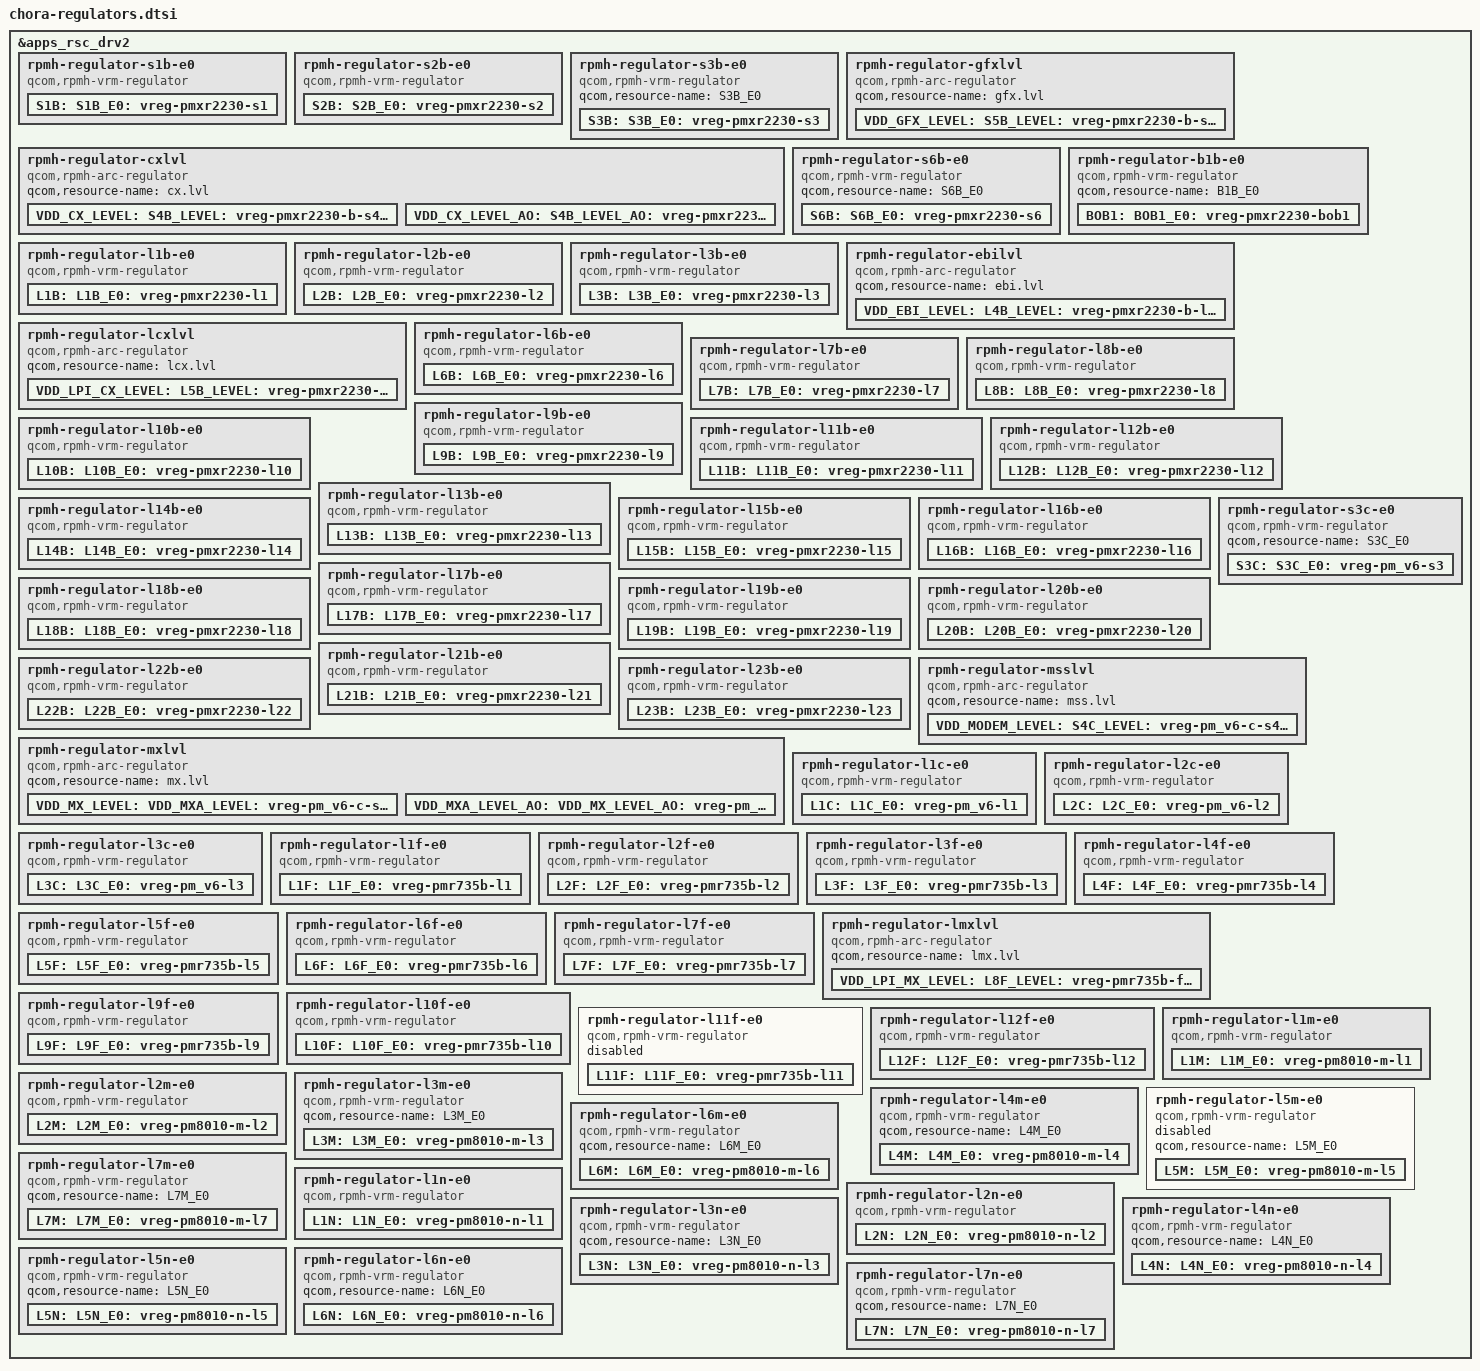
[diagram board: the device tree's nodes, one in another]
// SPDX-License-Identifier: BSD-3-Clause
/*
 * Copyright (c) Qualcomm Technologies, Inc. and/or its subsidiaries.
 */

#include <dt-bindings/regulator/qcom,rpmh-regulator-levels.h>

&apps_rsc_drv2 {
	rpmh-regulator-s1b-e0 {
		compatible = "qcom,rpmh-vrm-regulator";
		qcom,resource-name = "S1B_E0";
		qcom,regulator-type = "pmic5-ftsmps";
		qcom,supported-modes = <RPMH_REGULATOR_MODE_RET
					RPMH_REGULATOR_MODE_HPM>;
		qcom,mode-threshold-currents = <0 50000>;
		S1B: S1B_E0:
		pmxr2230_s1: vreg-pmxr2230-s1 {
			regulator-name = "pmxr2230_s1";
			qcom,set = <RPMH_REGULATOR_SET_ALL>;
			regulator-min-microvolt = <1800000>;
			regulator-max-microvolt = <2040000>;
			qcom,init-voltage = <1872000>;
			qcom,init-mode = <RPMH_REGULATOR_MODE_RET>;
		};
	};

	rpmh-regulator-s2b-e0 {
		compatible = "qcom,rpmh-vrm-regulator";
		qcom,resource-name = "S2B_E0";
		qcom,regulator-type = "pmic5-ftsmps";
		qcom,supported-modes = <RPMH_REGULATOR_MODE_RET
					RPMH_REGULATOR_MODE_HPM>;
		qcom,mode-threshold-currents = <0 50000>;

		S2B: S2B_E0:
		pmxr2230_s2: vreg-pmxr2230-s2 {
			regulator-name = "pmxr2230_s2";
			qcom,set = <RPMH_REGULATOR_SET_ALL>;
			regulator-min-microvolt = <1240000>;
			regulator-max-microvolt = <1408000>;
			qcom,init-voltage = <1256000>;
			qcom,init-mode = <RPMH_REGULATOR_MODE_RET>;
		};
	};

	rpmh-regulator-s3b-e0 {
		compatible = "qcom,rpmh-vrm-regulator";
		qcom,resource-name = "S3B_E0";
		S3B: S3B_E0:
		pmxr2230_s3: vreg-pmxr2230-s3 {
			regulator-name = "pmxr2230_s3";
			qcom,set = <RPMH_REGULATOR_SET_ALL>;
			regulator-min-microvolt = <920000>;
			regulator-max-microvolt = <1100000>;
			qcom,init-voltage = <952000>;
		};
	};

	rpmh-regulator-cxlvl {
		compatible = "qcom,rpmh-arc-regulator";
		qcom,resource-name = "cx.lvl";
		VDD_CX_LEVEL:
		S4B_LEVEL: S4B_E0_LEVEL:
		pmxr2230_b_s4_level: vreg-pmxr2230-b-s4-level {
			regulator-name = "pmxr2230_b_s4_level";
			qcom,set = <RPMH_REGULATOR_SET_ALL>;
			regulator-min-microvolt =
				<RPMH_REGULATOR_LEVEL_RETENTION>;
			regulator-max-microvolt =
				<RPMH_REGULATOR_LEVEL_MAX>;
			qcom,init-voltage-level =
				<RPMH_REGULATOR_LEVEL_TURBO>;
			proxy-supply = <&VDD_CX_LEVEL>;
			qcom,proxy-consumer-enable;
			qcom,proxy-consumer-voltage =
				<RPMH_REGULATOR_LEVEL_TURBO
				RPMH_REGULATOR_LEVEL_MAX>;
		};

		VDD_CX_LEVEL_AO: S4B_LEVEL_AO: S4B_E0_LEVEL_AO:
		pmxr2230_b_s4_level_ao: vreg-pmxr2230-b-s4-level-ao {
			regulator-name = "pmxr2230_b_s4_level_ao";
			qcom,set = <RPMH_REGULATOR_SET_ACTIVE>;
			regulator-min-microvolt =
				<RPMH_REGULATOR_LEVEL_RETENTION>;
			regulator-max-microvolt =
				<RPMH_REGULATOR_LEVEL_MAX>;
			qcom,init-voltage-level =
				<RPMH_REGULATOR_LEVEL_RETENTION>;
		};
	};

	rpmh-regulator-gfxlvl {
		compatible = "qcom,rpmh-arc-regulator";
		qcom,resource-name = "gfx.lvl";
		VDD_GFX_LEVEL:
		S5B_LEVEL: S5B_E0_LEVEL:
		pmxr2230_b_s5_level: vreg-pmxr2230-b-s5-level {
			regulator-name = "pmxr2230_b_s5_level";
			qcom,set = <RPMH_REGULATOR_SET_ALL>;
			regulator-min-microvolt =
				<RPMH_REGULATOR_LEVEL_RETENTION>;
			regulator-max-microvolt =
				<RPMH_REGULATOR_LEVEL_MAX>;
			qcom,init-voltage-level =
				<RPMH_REGULATOR_LEVEL_RETENTION>;
		};
	};

	rpmh-regulator-s6b-e0 {
		compatible = "qcom,rpmh-vrm-regulator";
		qcom,resource-name = "S6B_E0";
		S6B: S6B_E0:
		pmxr2230_s6: vreg-pmxr2230-s6 {
			regulator-name = "pmxr2230_s6";
			qcom,set = <RPMH_REGULATOR_SET_ALL>;
			regulator-min-microvolt = <300000>;
			regulator-max-microvolt = <650000>;
			qcom,init-voltage = <500000>;
		};
	};

	rpmh-regulator-b1b-e0 {
		compatible = "qcom,rpmh-vrm-regulator";
		qcom,resource-name = "B1B_E0";
		BOB1: BOB1_E0: pmxr2230_bob1: vreg-pmxr2230-bob1 {
			regulator-name = "pmxr2230_bob1";
			qcom,set = <RPMH_REGULATOR_SET_ALL>;
			regulator-min-microvolt = <2500000>;
			regulator-max-microvolt = <4500000>;
			qcom,init-voltage = <3328000>;
		};
	};

	rpmh-regulator-l1b-e0 {
		compatible = "qcom,rpmh-vrm-regulator";
		qcom,resource-name = "L1B_E0";
		qcom,regulator-type = "pmic5-ldo";
		qcom,supported-modes = <RPMH_REGULATOR_MODE_LPM
					RPMH_REGULATOR_MODE_HPM>;
		qcom,mode-threshold-currents = <0 30000>;
		qcom,disable-mode = <RPMH_REGULATOR_MODE_RET>;
		L1B: L1B_E0:
		pmxr2230_l1: vreg-pmxr2230-l1 {
			regulator-name = "pmxr2230_l1";
			qcom,set = <RPMH_REGULATOR_SET_ALL>;
			regulator-min-microvolt = <1800000>;
			regulator-max-microvolt = <1980000>;
			qcom,init-voltage = <1800000>;
			qcom,init-mode = <RPMH_REGULATOR_MODE_HPM>;
		};
	};

	rpmh-regulator-l2b-e0 {
		compatible = "qcom,rpmh-vrm-regulator";
		qcom,resource-name = "L2B_E0";
		qcom,regulator-type = "pmic5-ldo";
		qcom,supported-modes = <RPMH_REGULATOR_MODE_LPM
					RPMH_REGULATOR_MODE_HPM>;
		qcom,mode-threshold-currents = <0 30000>;
		proxy-supply = <&L2B>;
		L2B: L2B_E0:
		pmxr2230_l2: vreg-pmxr2230-l2 {
			regulator-name = "pmxr2230_l2";
			qcom,set = <RPMH_REGULATOR_SET_ALL>;
			regulator-min-microvolt = <720000>;
			regulator-max-microvolt = <958000>;
			qcom,init-voltage = <880000>;
			qcom,init-mode = <RPMH_REGULATOR_MODE_HPM>;
			qcom,proxy-consumer-enable;
			qcom,proxy-consumer-current = <98000>;
		};
	};

	rpmh-regulator-l3b-e0 {
		compatible = "qcom,rpmh-vrm-regulator";
		qcom,resource-name = "L3B_E0";
		qcom,regulator-type = "pmic5-ldo";
		qcom,supported-modes = <RPMH_REGULATOR_MODE_LPM
					RPMH_REGULATOR_MODE_HPM>;
		qcom,mode-threshold-currents = <0 30000>;
		L3B: L3B_E0:
		pmxr2230_l3: vreg-pmxr2230-l3 {
			regulator-name = "pmxr2230_l3";
			qcom,set = <RPMH_REGULATOR_SET_ALL>;
			regulator-min-microvolt = <870000>;
			regulator-max-microvolt = <970000>;
			qcom,init-voltage = <904000>;
			qcom,init-mode = <RPMH_REGULATOR_MODE_HPM>;
		};
	};

	rpmh-regulator-ebilvl {
		compatible = "qcom,rpmh-arc-regulator";
		qcom,resource-name = "ebi.lvl";
		VDD_EBI_LEVEL:
		L4B_LEVEL: L4B_E0_LEVEL:
		pmxr2230_b_l4_level: vreg-pmxr2230-b-l4-level {
			regulator-name = "pmxr2230_b_l4_level";
			qcom,set = <RPMH_REGULATOR_SET_ALL>;
			regulator-min-microvolt =
				<RPMH_REGULATOR_LEVEL_RETENTION>;
			regulator-max-microvolt =
				<RPMH_REGULATOR_LEVEL_MAX>;
			qcom,init-voltage-level =
				<RPMH_REGULATOR_LEVEL_RETENTION>;
		};
	};

	rpmh-regulator-lcxlvl {
		compatible = "qcom,rpmh-arc-regulator";
		qcom,resource-name = "lcx.lvl";
		VDD_LPI_CX_LEVEL:
		L5B_LEVEL: L5B_E0_LEVEL:
		pmxr2230_b_l5_level: vreg-pmxr2230-b-l5-level {
			regulator-name = "pmxr2230_b_l5_level";
			qcom,set = <RPMH_REGULATOR_SET_ALL>;
			regulator-min-microvolt =
				<RPMH_REGULATOR_LEVEL_RETENTION>;
			regulator-max-microvolt =
				<RPMH_REGULATOR_LEVEL_MAX>;
			qcom,init-voltage-level =
				<RPMH_REGULATOR_LEVEL_RETENTION>;
		};
	};

	rpmh-regulator-l6b-e0 {
		compatible = "qcom,rpmh-vrm-regulator";
		qcom,resource-name = "L6B_E0";
		qcom,regulator-type = "pmic5-ldo";
		qcom,supported-modes = <RPMH_REGULATOR_MODE_LPM
					RPMH_REGULATOR_MODE_HPM>;
		qcom,mode-threshold-currents = <0 30000>;
		L6B: L6B_E0:
		pmxr2230_l6: vreg-pmxr2230-l6 {
			regulator-name = "pmxr2230_l6";
			qcom,set = <RPMH_REGULATOR_SET_ALL>;
			regulator-min-microvolt = <1170000>;
			regulator-max-microvolt = <1370000>;
			qcom,init-voltage = <1200000>;
			qcom,init-mode = <RPMH_REGULATOR_MODE_HPM>;
		};
	};

	rpmh-regulator-l7b-e0 {
		compatible = "qcom,rpmh-vrm-regulator";
		qcom,resource-name = "L7B_E0";
		qcom,regulator-type = "pmic5-ldo";
		qcom,supported-modes = <RPMH_REGULATOR_MODE_LPM
					RPMH_REGULATOR_MODE_HPM>;
		qcom,mode-threshold-currents = <0 30000>;
		L7B: L7B_E0:
		pmxr2230_l7: vreg-pmxr2230-l7 {
			regulator-name = "pmxr2230_l7";
			qcom,set = <RPMH_REGULATOR_SET_ALL>;
			regulator-min-microvolt = <1800000>;
			regulator-max-microvolt = <2000000>;
			qcom,init-voltage = <1800000>;
			qcom,init-mode = <RPMH_REGULATOR_MODE_HPM>;
		};
	};

	rpmh-regulator-l8b-e0 {
		compatible = "qcom,rpmh-vrm-regulator";
		qcom,resource-name = "L8B_E0";
		qcom,regulator-type = "pmic5-ldo";
		qcom,supported-modes = <RPMH_REGULATOR_MODE_LPM
					RPMH_REGULATOR_MODE_HPM>;
		qcom,mode-threshold-currents = <0 30000>;
		L8B: L8B_E0:
		pmxr2230_l8: vreg-pmxr2230-l8 {
			regulator-name = "pmxr2230_l8";
			qcom,set = <RPMH_REGULATOR_SET_ALL>;
			regulator-min-microvolt = <320000>;
			regulator-max-microvolt = <2000000>;
			qcom,init-voltage = <320000>;
			qcom,init-mode = <RPMH_REGULATOR_MODE_HPM>;
		};
	};

	rpmh-regulator-l9b-e0 {
		compatible = "qcom,rpmh-vrm-regulator";
		qcom,resource-name = "L9B_E0";
		qcom,regulator-type = "pmic5-ldo";
		qcom,supported-modes = <RPMH_REGULATOR_MODE_LPM
					RPMH_REGULATOR_MODE_HPM>;
		qcom,mode-threshold-currents = <0 30000>;
		proxy-supply = <&L9B>;
		L9B: L9B_E0:
		pmxr2230_l9: vreg-pmxr2230-l9 {
			regulator-name = "pmxr2230_l9";
			qcom,set = <RPMH_REGULATOR_SET_ALL>;
			regulator-min-microvolt = <1650000>;
			regulator-max-microvolt = <2000000>;
			qcom,init-voltage = <1650000>;
			qcom,init-mode = <RPMH_REGULATOR_MODE_HPM>;
			qcom,proxy-consumer-enable;
			qcom,proxy-consumer-current = <220000>;
		};
	};

	rpmh-regulator-l10b-e0 {
		compatible = "qcom,rpmh-vrm-regulator";
		qcom,resource-name = "L10B_E0";
		qcom,regulator-type = "pmic5-ldo";
		qcom,supported-modes = <RPMH_REGULATOR_MODE_LPM
					RPMH_REGULATOR_MODE_HPM>;
		qcom,mode-threshold-currents = <0 30000>;
		L10B: L10B_E0:
		pmxr2230_l10: vreg-pmxr2230-l10 {
			regulator-name = "pmxr2230_l10";
			qcom,set = <RPMH_REGULATOR_SET_ALL>;
			regulator-min-microvolt = <1080000>;
			regulator-max-microvolt = <2000000>;
			qcom,init-voltage = <1080000>;
			qcom,init-mode = <RPMH_REGULATOR_MODE_HPM>;
		};
	};

	rpmh-regulator-l11b-e0 {
		compatible = "qcom,rpmh-vrm-regulator";
		qcom,resource-name = "L11B_E0";
		qcom,regulator-type = "pmic5-ldo";
		qcom,supported-modes = <RPMH_REGULATOR_MODE_LPM
					RPMH_REGULATOR_MODE_HPM>;
		qcom,mode-threshold-currents = <0 30000>;
		L11B: L11B_E0:
		pmxr2230_l11: vreg-pmxr2230-l11 {
			regulator-name = "pmxr2230_l11";
			qcom,set = <RPMH_REGULATOR_SET_ALL>;
			regulator-min-microvolt = <1080000>;
			regulator-max-microvolt = <1320000>;
			qcom,init-voltage = <1080000>;
			qcom,init-mode = <RPMH_REGULATOR_MODE_HPM>;
		};
	};

	rpmh-regulator-l12b-e0 {
		compatible = "qcom,rpmh-vrm-regulator";
		qcom,resource-name = "L12B_E0";
		qcom,regulator-type = "pmic5-ldo";
		qcom,supported-modes = <RPMH_REGULATOR_MODE_LPM
					RPMH_REGULATOR_MODE_HPM>;
		qcom,mode-threshold-currents = <0 80000>;
		L12B: L12B_E0:
		pmxr2230_l12: vreg-pmxr2230-l12 {
			regulator-name = "pmxr2230_l12";
			qcom,set = <RPMH_REGULATOR_SET_ALL>;
			qcom,init-mode = <RPMH_REGULATOR_MODE_HPM>;
		};
	};

	rpmh-regulator-l13b-e0 {
		compatible = "qcom,rpmh-vrm-regulator";
		qcom,resource-name = "L13B_E0";
		qcom,regulator-type = "pmic5-ldo";
		qcom,supported-modes = <RPMH_REGULATOR_MODE_LPM
					RPMH_REGULATOR_MODE_HPM>;
		qcom,mode-threshold-currents = <0 80000>;
		L13B: L13B_E0:
		pmxr2230_l13: vreg-pmxr2230-l13 {
			regulator-name = "pmxr2230_l13";
			qcom,set = <RPMH_REGULATOR_SET_ALL>;
			regulator-min-microvolt = <2700000>;
			regulator-max-microvolt = <3300000>;
			qcom,init-voltage = <2700000>;
			qcom,init-mode = <RPMH_REGULATOR_MODE_HPM>;
		};
	};

	rpmh-regulator-l14b-e0 {
		compatible = "qcom,rpmh-vrm-regulator";
		qcom,resource-name = "L14B_E0";
		qcom,regulator-type = "pmic5-ldo";
		qcom,supported-modes = <RPMH_REGULATOR_MODE_LPM
					RPMH_REGULATOR_MODE_HPM>;
		qcom,mode-threshold-currents = <0 10000>;
		L14B: L14B_E0:
		pmxr2230_l14: vreg-pmxr2230-l14 {
			regulator-name = "pmxr2230_l14";
			qcom,set = <RPMH_REGULATOR_SET_ALL>;
			regulator-min-microvolt = <3125000>;
			regulator-max-microvolt = <3465000>;
			qcom,init-voltage = <3125000>;
			qcom,init-mode = <RPMH_REGULATOR_MODE_HPM>;
		};
	};

	rpmh-regulator-l15b-e0 {
		compatible = "qcom,rpmh-vrm-regulator";
		qcom,resource-name = "L15B_E0";
		qcom,regulator-type = "pmic5-ldo";
		qcom,supported-modes = <RPMH_REGULATOR_MODE_LPM
					RPMH_REGULATOR_MODE_HPM>;
		qcom,mode-threshold-currents = <0 10000>;
		L15B: L15B_E0:
		pmxr2230_l15: vreg-pmxr2230-l15 {
			regulator-name = "pmxr2230_l15";
			qcom,set = <RPMH_REGULATOR_SET_ALL>;
			regulator-min-microvolt = <3125000>;
			regulator-max-microvolt = <3465000>;
			qcom,init-voltage = <3125000>;
			qcom,init-mode = <RPMH_REGULATOR_MODE_HPM>;
		};
	};

	rpmh-regulator-l16b-e0 {
		compatible = "qcom,rpmh-vrm-regulator";
		qcom,resource-name = "L16B_E0";
		qcom,regulator-type = "pmic5-ldo";
		qcom,supported-modes = <RPMH_REGULATOR_MODE_LPM
					RPMH_REGULATOR_MODE_HPM>;
		qcom,mode-threshold-currents = <0 10000>;
		L16B: L16B_E0:
		pmxr2230_l16: vreg-pmxr2230-l16 {
			regulator-name = "pmxr2230_l16";
			qcom,set = <RPMH_REGULATOR_SET_ALL>;
			regulator-min-microvolt = <2900000>;
			regulator-max-microvolt = <3544000>;
			qcom,init-voltage = <2900000>;
			qcom,init-mode = <RPMH_REGULATOR_MODE_HPM>;
		};
	};

	rpmh-regulator-l17b-e0 {
		compatible = "qcom,rpmh-vrm-regulator";
		qcom,resource-name = "L17B_E0";
		qcom,regulator-type = "pmic5-ldo";
		qcom,supported-modes = <RPMH_REGULATOR_MODE_LPM
					RPMH_REGULATOR_MODE_HPM>;
		qcom,mode-threshold-currents = <0 10000>;
		L17B: L17B_E0:
		pmxr2230_l17: vreg-pmxr2230-l17 {
			regulator-name = "pmxr2230_l17";
			qcom,set = <RPMH_REGULATOR_SET_ALL>;
			regulator-min-microvolt = <2700000>;
			regulator-max-microvolt = <3544000>;
			qcom,init-voltage = <3104000>;
			qcom,init-mode = <RPMH_REGULATOR_MODE_HPM>;
		};
	};

	rpmh-regulator-l18b-e0 {
		compatible = "qcom,rpmh-vrm-regulator";
		qcom,resource-name = "L18B_E0";
		qcom,regulator-type = "pmic5-ldo";
		qcom,supported-modes = <RPMH_REGULATOR_MODE_LPM
					RPMH_REGULATOR_MODE_HPM>;
		qcom,mode-threshold-currents = <0 10000>;
		L18B: L18B_E0:
		pmxr2230_l18: vreg-pmxr2230-l18 {
			regulator-name = "pmxr2230_l18";
			qcom,set = <RPMH_REGULATOR_SET_ALL>;
			regulator-min-microvolt = <1600000>;
			regulator-max-microvolt = <3544000>;
			qcom,init-voltage = <1600000>;
			qcom,init-mode = <RPMH_REGULATOR_MODE_HPM>;
		};
	};

	rpmh-regulator-l19b-e0 {
		compatible = "qcom,rpmh-vrm-regulator";
		qcom,resource-name = "L19B_E0";
		qcom,regulator-type = "pmic5-ldo";
		qcom,supported-modes = <RPMH_REGULATOR_MODE_LPM
					RPMH_REGULATOR_MODE_HPM>;
		qcom,mode-threshold-currents = <0 10000>;
		proxy-supply = <&L19B>;
		L19B: L19B_E0:
		pmxr2230_l19: vreg-pmxr2230-l19 {
			regulator-name = "pmxr2230_l19";
			qcom,set = <RPMH_REGULATOR_SET_ALL>;
			regulator-min-microvolt = <2600000>;
			regulator-max-microvolt = <3544000>;
			qcom,init-voltage = <2600000>;
			qcom,init-mode = <RPMH_REGULATOR_MODE_HPM>;
			qcom,proxy-consumer-enable;
			qcom,proxy-consumer-current = <10000>;
		};
	};

	rpmh-regulator-l20b-e0 {
		compatible = "qcom,rpmh-vrm-regulator";
		qcom,resource-name = "L20B_E0";
		qcom,regulator-type = "pmic5-ldo";
		qcom,supported-modes = <RPMH_REGULATOR_MODE_LPM
					RPMH_REGULATOR_MODE_HPM>;
		qcom,mode-threshold-currents = <0 10000>;
		L20B: L20B_E0:
		pmxr2230_l20: vreg-pmxr2230-l20 {
			regulator-name = "pmxr2230_l20";
			qcom,set = <RPMH_REGULATOR_SET_ALL>;
			regulator-min-microvolt = <1504000>;
			regulator-max-microvolt = <3544000>;
			qcom,init-voltage = <1504000>;
			qcom,init-mode = <RPMH_REGULATOR_MODE_HPM>;
		};
	};

	rpmh-regulator-l21b-e0 {
		compatible = "qcom,rpmh-vrm-regulator";
		qcom,resource-name = "L21B_E0";
		qcom,regulator-type = "pmic5-ldo";
		qcom,supported-modes = <RPMH_REGULATOR_MODE_LPM
					RPMH_REGULATOR_MODE_HPM>;
		qcom,mode-threshold-currents = <0 10000>;
		L21B: L21B_E0:
		pmxr2230_l21: vreg-pmxr2230-l21 {
			regulator-name = "pmxr2230_l21";
			qcom,set = <RPMH_REGULATOR_SET_ALL>;
			regulator-min-microvolt = <1504000>;
			regulator-max-microvolt = <3544000>;
			qcom,init-voltage = <1504000>;
			qcom,init-mode = <RPMH_REGULATOR_MODE_HPM>;
		};
	};

	rpmh-regulator-l22b-e0 {
		compatible = "qcom,rpmh-vrm-regulator";
		qcom,resource-name = "L22B_E0";
		qcom,regulator-type = "pmic5-ldo";
		qcom,supported-modes = <RPMH_REGULATOR_MODE_LPM
					RPMH_REGULATOR_MODE_HPM>;
		qcom,mode-threshold-currents = <0 10000>;
		L22B: L22B_E0:
		pmxr2230_l22: vreg-pmxr2230-l22 {
			regulator-name = "pmxr2230_l22";
			qcom,set = <RPMH_REGULATOR_SET_ALL>;
			regulator-min-microvolt = <2700000>;
			regulator-max-microvolt = <3400000>;
			qcom,init-voltage = <2700000>;
			qcom,init-mode = <RPMH_REGULATOR_MODE_HPM>;
		};
	};

	rpmh-regulator-l23b-e0 {
		compatible = "qcom,rpmh-vrm-regulator";
		qcom,resource-name = "L23B_E0";
		qcom,regulator-type = "pmic5-ldo";
		qcom,supported-modes = <RPMH_REGULATOR_MODE_LPM
					RPMH_REGULATOR_MODE_HPM>;
		qcom,mode-threshold-currents = <0 10000>;
		L23B: L23B_E0:
		pmxr2230_l23: vreg-pmxr2230-l23 {
			regulator-name = "pmxr2230_l23";
			qcom,set = <RPMH_REGULATOR_SET_ALL>;
			regulator-min-microvolt = <1650000>;
			regulator-max-microvolt = <3544000>;
			qcom,init-voltage = <1650000>;
			qcom,init-mode = <RPMH_REGULATOR_MODE_HPM>;
		};
	};

	rpmh-regulator-s3c-e0 {
		compatible = "qcom,rpmh-vrm-regulator";
		qcom,resource-name = "S3C_E0";
		S3C: S3C_E0:
		pm_v6_s3: vreg-pm_v6-s3 {
			regulator-name = "pm_v6_s3";
			qcom,set = <RPMH_REGULATOR_SET_ALL>;
			regulator-min-microvolt = <1010000>;
			regulator-max-microvolt = <1170000>;
			qcom,init-voltage = <1052000>;
		};
	};

	rpmh-regulator-msslvl {
		compatible = "qcom,rpmh-arc-regulator";
		qcom,resource-name = "mss.lvl";
		VDD_MODEM_LEVEL:
		S4C_LEVEL: S4C_E0_LEVEL:
		pm_v6_c_s4_level: vreg-pm_v6-c-s4-level {
			regulator-name = "pm_v6_c_s4_level";
			qcom,set = <RPMH_REGULATOR_SET_ALL>;
			regulator-min-microvolt =
				<RPMH_REGULATOR_LEVEL_RETENTION>;
			regulator-max-microvolt =
				<RPMH_REGULATOR_LEVEL_MAX>;
			qcom,init-voltage-level =
				<RPMH_REGULATOR_LEVEL_RETENTION>;
		};
	};

	rpmh-regulator-mxlvl {
		compatible = "qcom,rpmh-arc-regulator";
		qcom,resource-name = "mx.lvl";
		VDD_MX_LEVEL:
		VDD_MXA_LEVEL:
		S5C_LEVEL: S5C_E0_LEVEL:
		pm_v6_c_s5_level: vreg-pm_v6-c-s5-level {
			regulator-name = "pm_v6_c_s5_level";
			qcom,set = <RPMH_REGULATOR_SET_ALL>;
			regulator-min-microvolt =
				<RPMH_REGULATOR_LEVEL_RETENTION>;
			regulator-max-microvolt =
				<RPMH_REGULATOR_LEVEL_MAX>;
			qcom,init-voltage-level =
				<RPMH_REGULATOR_LEVEL_TURBO>;
			proxy-supply = <&VDD_MXA_LEVEL>;
			qcom,proxy-consumer-enable;
			qcom,proxy-consumer-voltage =
				<RPMH_REGULATOR_LEVEL_TURBO
				RPMH_REGULATOR_LEVEL_MAX>;
		};

		VDD_MXA_LEVEL_AO: VDD_MX_LEVEL_AO:
		S5C_LEVEL_AO: S5C_E0_LEVEL_AO:
		pm_v6_c_s5_level_ao: vreg-pm_v6-c-s5-level-ao {
			regulator-name = "pm_v6_c_s5_level_ao";
			qcom,set = <RPMH_REGULATOR_SET_ACTIVE>;
			regulator-min-microvolt =
				<RPMH_REGULATOR_LEVEL_RETENTION>;
			regulator-max-microvolt =
				<RPMH_REGULATOR_LEVEL_MAX>;
			qcom,init-voltage-level =
				<RPMH_REGULATOR_LEVEL_RETENTION>;
		};
	};

	rpmh-regulator-l1c-e0 {
		compatible = "qcom,rpmh-vrm-regulator";
		qcom,resource-name = "L1C_E0";
		qcom,regulator-type = "pmic5-ldo";
		qcom,supported-modes = <RPMH_REGULATOR_MODE_LPM
					RPMH_REGULATOR_MODE_HPM>;
		qcom,mode-threshold-currents = <0 1>;
		L1C: L1C_E0:
		pm_v6_l1: vreg-pm_v6-l1 {
			regulator-name = "pm_v6_l1";
			qcom,set = <RPMH_REGULATOR_SET_ALL>;
			regulator-min-microvolt = <320000>;
			regulator-max-microvolt = <650000>;
			qcom,init-voltage = <504000>;
			qcom,init-mode = <RPMH_REGULATOR_MODE_HPM>;
		};
	};

	rpmh-regulator-l2c-e0 {
		compatible = "qcom,rpmh-vrm-regulator";
		qcom,resource-name = "L2C_E0";
		qcom,regulator-type = "pmic5-ldo";
		qcom,supported-modes = <RPMH_REGULATOR_MODE_LPM
					RPMH_REGULATOR_MODE_HPM>;
		qcom,mode-threshold-currents = <0 30000>;
		L2C: L2C_E0:
		pm_v6_l2: vreg-pm_v6-l2 {
			regulator-name = "pm_v6_l2";
			qcom,set = <RPMH_REGULATOR_SET_ALL>;
			qcom,init-mode = <RPMH_REGULATOR_MODE_HPM>;
		};
	};

	rpmh-regulator-l3c-e0 {
		compatible = "qcom,rpmh-vrm-regulator";
		qcom,resource-name = "L3C_E0";
		qcom,regulator-type = "pmic5-ldo";
		qcom,supported-modes = <RPMH_REGULATOR_MODE_LPM
					RPMH_REGULATOR_MODE_HPM>;
		qcom,mode-threshold-currents = <0 1>;
		proxy-supply = <&L3C>;
		L3C: L3C_E0:
		pm_v6_l3: vreg-pm_v6-l3 {
			regulator-name = "pm_v6_l3";
			qcom,set = <RPMH_REGULATOR_SET_ALL>;
			regulator-min-microvolt = <1080000>;
			regulator-max-microvolt = <1320000>;
			qcom,init-voltage = <1200000>;
			qcom,init-mode = <RPMH_REGULATOR_MODE_HPM>;
			qcom,proxy-consumer-enable;
			qcom,proxy-consumer-current = <16600>;
		};
	};

	rpmh-regulator-l1f-e0 {
		compatible = "qcom,rpmh-vrm-regulator";
		qcom,resource-name = "L1F_E0";
		qcom,regulator-type = "pmic5-ldo";
		qcom,supported-modes = <RPMH_REGULATOR_MODE_LPM
					RPMH_REGULATOR_MODE_HPM>;
		qcom,mode-threshold-currents = <0 30000>;
		L1F: L1F_E0:
		pmr735b_l1: vreg-pmr735b-l1 {
			regulator-name = "pmr735b_l1";
			qcom,set = <RPMH_REGULATOR_SET_ALL>;
			regulator-min-microvolt = <852000>;
			regulator-max-microvolt = <950000>;
			qcom,init-voltage = <852000>;
			qcom,init-mode = <RPMH_REGULATOR_MODE_HPM>;
		};
	};

	rpmh-regulator-l2f-e0 {
		compatible = "qcom,rpmh-vrm-regulator";
		qcom,resource-name = "L2F_E0";
		qcom,regulator-type = "pmic5-ldo";
		qcom,supported-modes = <RPMH_REGULATOR_MODE_LPM
					RPMH_REGULATOR_MODE_HPM>;
		qcom,mode-threshold-currents = <0 30000>;
		L2F: L2F_E0:
		pmr735b_l2: vreg-pmr735b-l2 {
			regulator-name = "pmr735b_l2";
			qcom,set = <RPMH_REGULATOR_SET_ALL>;
			regulator-min-microvolt = <751000>;
			regulator-max-microvolt = <824000>;
			qcom,init-voltage = <751000>;
			qcom,init-mode = <RPMH_REGULATOR_MODE_HPM>;
		};
	};

	rpmh-regulator-l3f-e0 {
		compatible = "qcom,rpmh-vrm-regulator";
		qcom,resource-name = "L3F_E0";
		qcom,regulator-type = "pmic5-ldo";
		qcom,supported-modes = <RPMH_REGULATOR_MODE_LPM
					RPMH_REGULATOR_MODE_HPM>;
		qcom,mode-threshold-currents = <0 30000>;
		L3F: L3F_E0:
		pmr735b_l3: vreg-pmr735b-l3 {
			regulator-name = "pmr735b_l3";
			qcom,set = <RPMH_REGULATOR_SET_ALL>;
			regulator-min-microvolt = <620000>;
			regulator-max-microvolt = <1050000>;
			qcom,init-voltage = <620000>;
			qcom,init-mode = <RPMH_REGULATOR_MODE_HPM>;
		};
	};

	rpmh-regulator-l4f-e0 {
		compatible = "qcom,rpmh-vrm-regulator";
		qcom,resource-name = "L4F_E0";
		qcom,regulator-type = "pmic5-ldo";
		qcom,supported-modes = <RPMH_REGULATOR_MODE_LPM
					RPMH_REGULATOR_MODE_HPM>;
		qcom,mode-threshold-currents = <0 10000>;
		L4F: L4F_E0:
		pmr735b_l4: vreg-pmr735b-l4 {
			regulator-name = "pmr735b_l4";
			qcom,set = <RPMH_REGULATOR_SET_ALL>;
			regulator-min-microvolt = <1600000>;
			regulator-max-microvolt = <2000000>;
			qcom,init-voltage = <1600000>;
			qcom,init-mode = <RPMH_REGULATOR_MODE_HPM>;
		};
	};

	rpmh-regulator-l5f-e0 {
		compatible = "qcom,rpmh-vrm-regulator";
		qcom,resource-name = "L5F_E0";
		qcom,regulator-type = "pmic5-ldo";
		qcom,supported-modes = <RPMH_REGULATOR_MODE_LPM
					RPMH_REGULATOR_MODE_HPM>;
		qcom,mode-threshold-currents = <0 30000>;
		L5F: L5F_E0:
		pmr735b_l5: vreg-pmr735b-l5 {
			regulator-name = "pmr735b_l5";
			qcom,set = <RPMH_REGULATOR_SET_ALL>;
			regulator-min-microvolt = <1200000>;
			regulator-max-microvolt = <1304000>;
			qcom,init-voltage = <1200000>;
			qcom,init-mode = <RPMH_REGULATOR_MODE_HPM>;
		};
	};

	rpmh-regulator-l6f-e0 {
		compatible = "qcom,rpmh-vrm-regulator";
		qcom,resource-name = "L6F_E0";
		qcom,regulator-type = "pmic5-ldo";
		qcom,supported-modes = <RPMH_REGULATOR_MODE_LPM
					RPMH_REGULATOR_MODE_HPM>;
		qcom,mode-threshold-currents = <0 30000>;
		proxy-supply = <&L6F>;
		L6F: L6F_E0:
		pmr735b_l6: vreg-pmr735b-l6 {
			regulator-name = "pmr735b_l6";
			qcom,set = <RPMH_REGULATOR_SET_ALL>;
			regulator-min-microvolt = <1150000>;
			regulator-max-microvolt = <1250000>;
			qcom,init-voltage = <1150000>;
			qcom,init-mode = <RPMH_REGULATOR_MODE_HPM>;
			qcom,proxy-consumer-enable;
			qcom,proxy-consumer-current = <200000>;
		};
	};

	rpmh-regulator-l7f-e0 {
		compatible = "qcom,rpmh-vrm-regulator";
		qcom,resource-name = "L7F_E0";
		qcom,regulator-type = "pmic5-ldo";
		qcom,supported-modes = <RPMH_REGULATOR_MODE_LPM
					RPMH_REGULATOR_MODE_HPM>;
		qcom,mode-threshold-currents = <0 30000>;
		L7F: L7F_E0:
		pmr735b_l7: vreg-pmr735b-l7 {
			regulator-name = "pmr735b_l7";
			qcom,set = <RPMH_REGULATOR_SET_ALL>;
			regulator-min-microvolt = <504000>;
			regulator-max-microvolt = <864000>;
			qcom,init-voltage = <504000>;
			qcom,init-mode = <RPMH_REGULATOR_MODE_HPM>;
		};
	};

	rpmh-regulator-lmxlvl {
		compatible = "qcom,rpmh-arc-regulator";
		qcom,resource-name = "lmx.lvl";
		VDD_LPI_MX_LEVEL:
		L8F_LEVEL: L8F_E0_LEVEL:
		pmr735b_f_l8_level: vreg-pmr735b-f-l8-level {
			regulator-name = "pmr735b_f_l8_level";
			qcom,set = <RPMH_REGULATOR_SET_ALL>;
			regulator-min-microvolt =
				<RPMH_REGULATOR_LEVEL_RETENTION>;
			regulator-max-microvolt =
				<RPMH_REGULATOR_LEVEL_MAX>;
			qcom,init-voltage-level =
				<RPMH_REGULATOR_LEVEL_RETENTION>;
		};
	};

	rpmh-regulator-l9f-e0 {
		compatible = "qcom,rpmh-vrm-regulator";
		qcom,resource-name = "L9F_E0";
		qcom,regulator-type = "pmic5-ldo";
		qcom,supported-modes = <RPMH_REGULATOR_MODE_LPM
					RPMH_REGULATOR_MODE_HPM>;
		qcom,mode-threshold-currents = <0 30000>;
		L9F: L9F_E0:
		pmr735b_l9: vreg-pmr735b-l9 {
			regulator-name = "pmr735b_l9";
			qcom,set = <RPMH_REGULATOR_SET_ALL>;
			regulator-min-microvolt = <1200000>;
			regulator-max-microvolt = <1304000>;
			qcom,init-voltage = <1200000>;
			qcom,init-mode = <RPMH_REGULATOR_MODE_HPM>;
		};
	};

	rpmh-regulator-l10f-e0 {
		compatible = "qcom,rpmh-vrm-regulator";
		qcom,resource-name = "L10F_E0";
		qcom,regulator-type = "pmic5-ldo";
		qcom,supported-modes = <RPMH_REGULATOR_MODE_LPM
					RPMH_REGULATOR_MODE_HPM>;
		qcom,mode-threshold-currents = <0 10000>;
		L10F: L10F_E0:
		pmr735b_l10: vreg-pmr735b-l10 {
			regulator-name = "pmr735b_l10";
			qcom,set = <RPMH_REGULATOR_SET_ALL>;
			regulator-min-microvolt = <1504000>;
			regulator-max-microvolt = <2000000>;
			qcom,init-voltage = <1504000>;
			qcom,init-mode = <RPMH_REGULATOR_MODE_HPM>;
		};
	};

	rpmh-regulator-l11f-e0 {
		compatible = "qcom,rpmh-vrm-regulator";
		qcom,resource-name = "L11F_E0";
		qcom,regulator-type = "pmic5-ldo";
		qcom,supported-modes = <RPMH_REGULATOR_MODE_LPM
					RPMH_REGULATOR_MODE_HPM>;
		qcom,mode-threshold-currents = <0 30000>;
		status = "disabled";
		L11F: L11F_E0:
		pmr735b_l11: vreg-pmr735b-l11 {
			regulator-name = "pmr735b_l11";
			qcom,set = <RPMH_REGULATOR_SET_ALL>;
			regulator-min-microvolt = <312000>;
			regulator-max-microvolt = <1304000>;
			qcom,init-voltage = <312000>;
			qcom,init-mode = <RPMH_REGULATOR_MODE_HPM>;
		};
	};

	rpmh-regulator-l12f-e0 {
		compatible = "qcom,rpmh-vrm-regulator";
		qcom,resource-name = "L12F_E0";
		qcom,regulator-type = "pmic5-ldo";
		qcom,supported-modes = <RPMH_REGULATOR_MODE_LPM
					RPMH_REGULATOR_MODE_HPM>;
		qcom,mode-threshold-currents = <0 30000>;
		L12F: L12F_E0:
		pmr735b_l12: vreg-pmr735b-l12 {
			regulator-name = "pmr735b_l12";
			qcom,set = <RPMH_REGULATOR_SET_ALL>;
			regulator-min-microvolt = <1080000>;
			regulator-max-microvolt = <1304000>;
			qcom,init-voltage = <1080000>;
			qcom,init-mode = <RPMH_REGULATOR_MODE_HPM>;
		};
	};

	rpmh-regulator-l1m-e0 {
		compatible = "qcom,rpmh-vrm-regulator";
		qcom,resource-name = "L1M_E0";
		qcom,regulator-type = "pmic5-ldo";
		qcom,supported-modes = <RPMH_REGULATOR_MODE_LPM
					RPMH_REGULATOR_MODE_HPM>;
		qcom,mode-threshold-currents = <0 100000>;
		L1M: L1M_E0:
		pm8010_m_l1: vreg-pm8010-m-l1 {
			regulator-name = "pm8010_m_l1";
			qcom,set = <RPMH_REGULATOR_SET_ALL>;
			regulator-min-microvolt = <1050000>;
			regulator-max-microvolt = <1180000>;
			qcom,init-voltage = <1050000>;
			qcom,init-mode = <RPMH_REGULATOR_MODE_HPM>;
		};
	};

	rpmh-regulator-l2m-e0 {
		compatible = "qcom,rpmh-vrm-regulator";
		qcom,resource-name = "L2M_E0";
		qcom,regulator-type = "pmic5-ldo";
		qcom,supported-modes = <RPMH_REGULATOR_MODE_LPM
					RPMH_REGULATOR_MODE_HPM>;
		qcom,mode-threshold-currents = <0 100000>;
		L2M: L2M_E0:
		pm8010_m_l2: vreg-pm8010-m-l2 {
			regulator-name = "pm8010_m_l2";
			qcom,set = <RPMH_REGULATOR_SET_ALL>;
			regulator-min-microvolt = <950000>;
			regulator-max-microvolt = <1150000>;
			qcom,init-voltage = <950000>;
			qcom,init-mode = <RPMH_REGULATOR_MODE_HPM>;
		};
	};

	rpmh-regulator-l3m-e0 {
		compatible = "qcom,rpmh-vrm-regulator";
		qcom,resource-name = "L3M_E0";

		L3M: L3M_E0:
		pm8010_m_l3: vreg-pm8010-m-l3 {
			regulator-name = "pm8010_m_l3";
			qcom,set = <RPMH_REGULATOR_SET_ALL>;
			regulator-min-microvolt = <2700000>;
			regulator-max-microvolt = <2900000>;
			qcom,init-voltage = <2700000>;
		};
	};

	rpmh-regulator-l4m-e0 {
		compatible = "qcom,rpmh-vrm-regulator";
		qcom,resource-name = "L4M_E0";

		L4M: L4M_E0:
		pm8010_m_l4: vreg-pm8010-m-l4 {
			regulator-name = "pm8010_m_l4";
			qcom,set = <RPMH_REGULATOR_SET_ALL>;
			regulator-min-microvolt = <2700000>;
			regulator-max-microvolt = <2900000>;
			qcom,init-voltage = <2700000>;
		};
	};

	rpmh-regulator-l5m-e0 {
		compatible = "qcom,rpmh-vrm-regulator";
		qcom,resource-name = "L5M_E0";

		status = "disabled";
		L5M: L5M_E0:
		pm8010_m_l5: vreg-pm8010-m-l5 {
			regulator-name = "pm8010_m_l5";
			qcom,set = <RPMH_REGULATOR_SET_ALL>;
			regulator-min-microvolt = <1504000>;
			regulator-max-microvolt = <3544000>;
			qcom,init-voltage = <1504000>;
		};
	};

	rpmh-regulator-l6m-e0 {
		compatible = "qcom,rpmh-vrm-regulator";
		qcom,resource-name = "L6M_E0";

		L6M: L6M_E0:
		pm8010_m_l6: vreg-pm8010-m-l6 {
			regulator-name = "pm8010_m_l6";
			qcom,set = <RPMH_REGULATOR_SET_ALL>;
			regulator-min-microvolt = <2700000>;
			regulator-max-microvolt = <2900000>;
			qcom,init-voltage = <2700000>;
		};
	};

	rpmh-regulator-l7m-e0 {
		compatible = "qcom,rpmh-vrm-regulator";
		qcom,resource-name = "L7M_E0";

		L7M: L7M_E0:
		pm8010_m_l7: vreg-pm8010-m-l7 {
			regulator-name = "pm8010_m_l7";
			qcom,set = <RPMH_REGULATOR_SET_ALL>;
			regulator-min-microvolt = <2700000>;
			regulator-max-microvolt = <3000000>;
			qcom,init-voltage = <2700000>;
		};
	};

	rpmh-regulator-l1n-e0 {
		compatible = "qcom,rpmh-vrm-regulator";
		qcom,resource-name = "L1N_E0";
		qcom,regulator-type = "pmic5-ldo";
		qcom,supported-modes = <RPMH_REGULATOR_MODE_LPM
					RPMH_REGULATOR_MODE_HPM>;
		qcom,mode-threshold-currents = <0 100000>;
		L1N: L1N_E0:
		pm8010_n_l1: vreg-pm8010-n-l1 {
			regulator-name = "pm8010_n_l1";
			qcom,set = <RPMH_REGULATOR_SET_ALL>;
			regulator-min-microvolt = <1050000>;
			regulator-max-microvolt = <1200000>;
			qcom,init-voltage = <1050000>;
			qcom,init-mode = <RPMH_REGULATOR_MODE_HPM>;
		};
	};

	rpmh-regulator-l2n-e0 {
		compatible = "qcom,rpmh-vrm-regulator";
		qcom,resource-name = "L2N_E0";
		qcom,regulator-type = "pmic5-ldo";
		qcom,supported-modes = <RPMH_REGULATOR_MODE_LPM
					RPMH_REGULATOR_MODE_HPM>;
		qcom,mode-threshold-currents = <0 100000>;
		L2N: L2N_E0:
		pm8010_n_l2: vreg-pm8010-n-l2 {
			regulator-name = "pm8010_n_l2";
			qcom,set = <RPMH_REGULATOR_SET_ALL>;
			regulator-min-microvolt = <950000>;
			regulator-max-microvolt = <1150000>;
			qcom,init-voltage = <950000>;
			qcom,init-mode = <RPMH_REGULATOR_MODE_HPM>;
		};
	};

	rpmh-regulator-l3n-e0 {
		compatible = "qcom,rpmh-vrm-regulator";
		qcom,resource-name = "L3N_E0";

		L3N: L3N_E0:
		pm8010_n_l3: vreg-pm8010-n-l3 {
			regulator-name = "pm8010_n_l3";
			qcom,set = <RPMH_REGULATOR_SET_ALL>;
			regulator-min-microvolt = <1792000>;
			regulator-max-microvolt = <1900000>;
			qcom,init-voltage = <1792000>;
		};
	};

	rpmh-regulator-l4n-e0 {
		compatible = "qcom,rpmh-vrm-regulator";
		qcom,resource-name = "L4N_E0";

		L4N: L4N_E0:
		pm8010_n_l4: vreg-pm8010-n-l4 {
			regulator-name = "pm8010_n_l4";
			qcom,set = <RPMH_REGULATOR_SET_ALL>;
			regulator-min-microvolt = <1792000>;
			regulator-max-microvolt = <1900000>;
			qcom,init-voltage = <1792000>;
		};
	};

	rpmh-regulator-l5n-e0 {
		compatible = "qcom,rpmh-vrm-regulator";
		qcom,resource-name = "L5N_E0";

		L5N: L5N_E0:
		pm8010_n_l5: vreg-pm8010-n-l5 {
			regulator-name = "pm8010_n_l5";
			qcom,set = <RPMH_REGULATOR_SET_ALL>;
			regulator-min-microvolt = <1620000>;
			regulator-max-microvolt = <1980000>;
			qcom,init-voltage = <1620000>;
		};
	};

	rpmh-regulator-l6n-e0 {
		compatible = "qcom,rpmh-vrm-regulator";
		qcom,resource-name = "L6N_E0";

		L6N: L6N_E0:
		pm8010_n_l6: vreg-pm8010-n-l6 {
			regulator-name = "pm8010_n_l6";
			qcom,set = <RPMH_REGULATOR_SET_ALL>;
			regulator-min-microvolt = <2700000>;
			regulator-max-microvolt = <2900000>;
			qcom,init-voltage = <2700000>;
		};
	};

	rpmh-regulator-l7n-e0 {
		compatible = "qcom,rpmh-vrm-regulator";
		qcom,resource-name = "L7N_E0";

		L7N: L7N_E0:
		pm8010_n_l7: vreg-pm8010-n-l7 {
			regulator-name = "pm8010_n_l7";
			qcom,set = <RPMH_REGULATOR_SET_ALL>;
			regulator-min-microvolt = <2500000>;
			regulator-max-microvolt = <3300000>;
			qcom,init-voltage = <2500000>;
		};
	};
};
